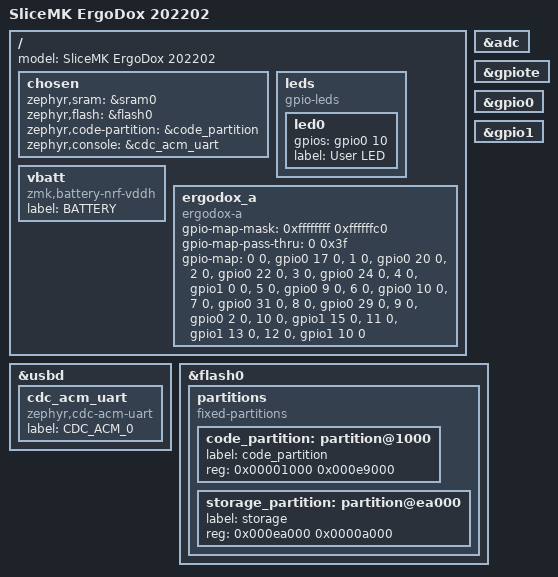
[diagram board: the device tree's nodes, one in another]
/dts-v1/;
#include <nordic/nrf52840_qiaa.dtsi>

/ {
	model = "SliceMK ErgoDox 202202";

	chosen {
		zephyr,sram = &sram0;
		zephyr,flash = &flash0;
		zephyr,code-partition = &code_partition;
		zephyr,console = &cdc_acm_uart;
	};

	leds {
		compatible = "gpio-leds";
		led0: led0 {
			gpios = <&gpio0 10 GPIO_ACTIVE_HIGH>;
			label = "User LED";
		};
	};

	// There is no battery so make pretend with VDDHDIV5.
	vbatt {
		compatible = "zmk,battery-nrf-vddh";
		label = "BATTERY";
	};

	ergodox_a: ergodox_a {
		compatible = "ergodox-a";
		#gpio-cells = <2>;
		gpio-map-mask = <0xffffffff 0xffffffc0>;
		gpio-map-pass-thru = <0 0x3f>;
		gpio-map
			= <0 0 &gpio0 17 0>
			, <1 0 &gpio0 20 0>
			, <2 0 &gpio0 22 0>
			, <3 0 &gpio0 24 0>
			, <4 0 &gpio1 0 0>
			, <5 0 &gpio0 9 0>
			, <6 0 &gpio0 10 0>
			, <7 0 &gpio0 31 0>
			, <8 0 &gpio0 29 0>
			, <9 0 &gpio0 2 0>
			, <10 0 &gpio1 15 0>
			, <11 0 &gpio1 13 0>
			, <12 0 &gpio1 10 0>
			;
	};
};

&adc {
	status = "okay";
};

&gpiote {
	status = "okay";
};

&gpio0 {
	status = "okay";
};

&gpio1 {
	status = "okay";
};

&usbd {
	status = "okay";
	cdc_acm_uart: cdc_acm_uart {
		compatible = "zephyr,cdc-acm-uart";
		label = "CDC_ACM_0";
	};
};

&flash0 {
	partitions {
		compatible = "fixed-partitions";
		#address-cells = <1>;
		#size-cells = <1>;

		code_partition: partition@1000 {
			label = "code_partition";
			reg = <0x00001000 0x000e9000>;
		};

		storage_partition: partition@ea000 {
			label = "storage";
			reg = <0x000ea000 0x0000a000>;
		};
	};
};
